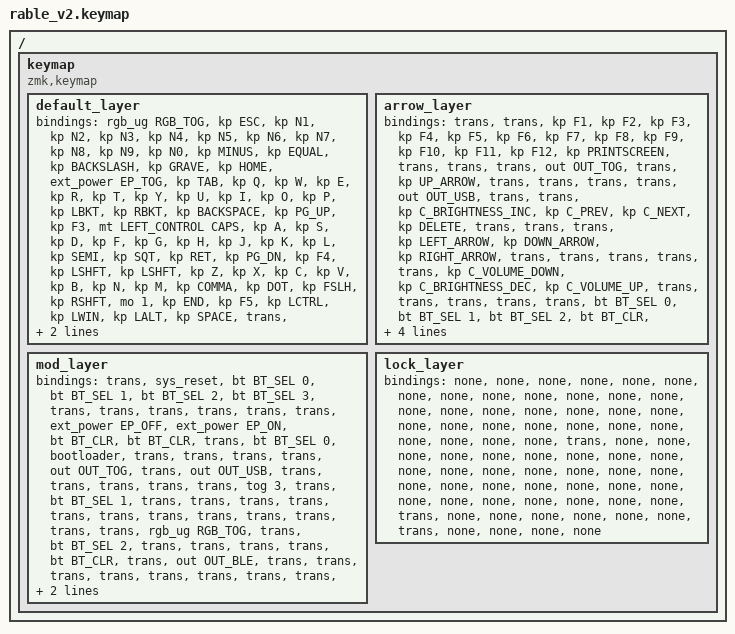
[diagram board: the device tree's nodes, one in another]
/*
 * Copyright (c) 2021 Nick Winans
 *
 * SPDX-License-Identifier: MIT
 */

#include <behaviors.dtsi>
#include <dt-bindings/zmk/bt.h>
#include <dt-bindings/zmk/ext_power.h>
#include <dt-bindings/zmk/keys.h>
#include <dt-bindings/zmk/outputs.h>
#include <dt-bindings/zmk/rgb.h>

/ {
    keymap {
        compatible = "zmk,keymap";

        default_layer {
            bindings = <
&rgb_ug RGB_TOG  &kp ESC  &kp N1  &kp N2  &kp N3  &kp N4  &kp N5  &kp N6  &kp N7  &kp N8  &kp N9  &kp N0  &kp MINUS  &kp EQUAL  &kp BACKSLASH  &kp GRAVE  &kp HOME  &ext_power EP_TOG  &kp TAB  &kp Q  &kp W  &kp E  &kp R  &kp T  &kp Y  &kp U  &kp I  &kp O  &kp P  &kp LBKT  &kp RBKT  &kp BACKSPACE  &kp PG_UP  &kp F3  &mt LEFT_CONTROL CAPS  &kp A  &kp S  &kp D  &kp F  &kp G  &kp H  &kp J  &kp K  &kp L  &kp SEMI  &kp SQT  &kp RET  &kp PG_DN  &kp F4  &kp LSHFT  &kp LSHFT  &kp Z  &kp X  &kp C  &kp V  &kp B  &kp N  &kp M  &kp COMMA  &kp DOT  &kp FSLH  &kp RSHFT  &mo 1  &kp END  &kp F5  &kp LCTRL  &kp LWIN  &kp LALT  &kp SPACE  &trans  &mt LEFT_WIN RIGHT_ALT  &kp RWIN  &kp RCTRL  &kp RIGHT
            >;
        };

        arrow_layer {
            bindings = <
&trans  &trans  &kp F1  &kp F2  &kp F3  &kp F4  &kp F5  &kp F6  &kp F7  &kp F8  &kp F9  &kp F10  &kp F11  &kp F12  &kp PRINTSCREEN  &trans  &trans  &trans  &out OUT_TOG  &trans  &kp UP_ARROW  &trans  &trans  &trans  &trans  &out OUT_USB  &trans  &trans  &kp C_BRIGHTNESS_INC  &kp C_PREV  &kp C_NEXT  &kp DELETE  &trans  &trans  &trans  &kp LEFT_ARROW  &kp DOWN_ARROW  &kp RIGHT_ARROW  &trans  &trans  &trans  &trans  &trans  &kp C_VOLUME_DOWN  &kp C_BRIGHTNESS_DEC  &kp C_VOLUME_UP  &trans  &trans  &trans  &trans  &trans  &bt BT_SEL 0  &bt BT_SEL 1  &bt BT_SEL 2  &bt BT_CLR  &out OUT_BLE  &trans  &trans  &trans  &trans  &trans  &kp C_PLAY_PAUSE  &trans  &trans  &trans  &trans  &trans  &kp LEFT_WIN  &trans  &trans  &trans  &trans  &trans  &trans
            >;
        };

        mod_layer {
            bindings = <
&trans  &sys_reset  &bt BT_SEL 0  &bt BT_SEL 1  &bt BT_SEL 2  &bt BT_SEL 3  &trans  &trans  &trans  &trans  &trans  &trans  &ext_power EP_OFF  &ext_power EP_ON  &bt BT_CLR  &bt BT_CLR  &trans  &bt BT_SEL 0  &bootloader  &trans  &trans  &trans  &trans  &out OUT_TOG  &trans  &out OUT_USB  &trans  &trans  &trans  &trans  &trans  &tog 3  &trans  &bt BT_SEL 1  &trans  &trans  &trans  &trans  &trans  &trans  &trans  &trans  &trans  &trans  &trans  &trans  &rgb_ug RGB_TOG  &trans  &bt BT_SEL 2  &trans  &trans  &trans  &trans  &bt BT_CLR  &trans  &out OUT_BLE  &trans  &trans  &trans  &trans  &trans  &trans  &trans  &trans  &bt BT_SEL 3  &trans  &trans  &trans  &trans  &trans  &trans  &trans  &trans  &trans
            >;
        };

        lock_layer {
            bindings = <
&none  &none  &none  &none  &none  &none  &none  &none  &none  &none  &none  &none  &none  &none  &none  &none  &none  &none  &none  &none  &none  &none  &none  &none  &none  &none  &none  &none  &none  &none  &none  &trans  &none  &none  &none  &none  &none  &none  &none  &none  &none  &none  &none  &none  &none  &none  &none  &none  &none  &none  &none  &none  &none  &none  &none  &none  &none  &none  &none  &none  &none  &none  &trans  &none  &none  &none  &none  &none  &none  &trans  &none  &none  &none  &none
            >;
        };
    };
};
